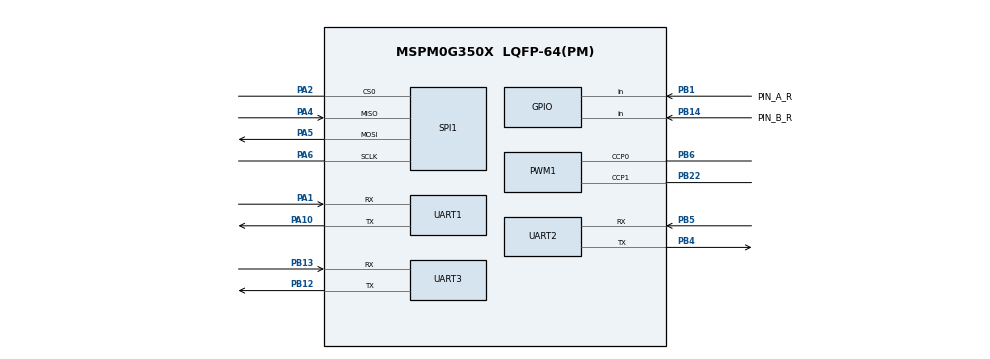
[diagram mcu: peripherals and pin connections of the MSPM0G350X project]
/**
 * @cliArgs --device "MSPM0G350X" --part "Default" --package "LQFP-64(PM)" --product "mspm0_sdk@2.05.01.00"
 * @versions {"tool":"1.24.0+4110"}
 */

/**
 * Import the modules used in this configuration.
 */
const GPIO   = scripting.addModule("/ti/driverlib/GPIO", {}, false);
const GPIO1  = GPIO.addInstance();
const GPIO2  = GPIO.addInstance();
const PWM    = scripting.addModule("/ti/driverlib/PWM", {}, false);
const PWM1   = PWM.addInstance();
const SPI    = scripting.addModule("/ti/driverlib/SPI", {}, false);
const SPI1   = SPI.addInstance();
const SYSCTL = scripting.addModule("/ti/driverlib/SYSCTL");
const TIMER  = scripting.addModule("/ti/driverlib/TIMER", {}, false);
const TIMER1 = TIMER.addInstance();
const UART   = scripting.addModule("/ti/driverlib/UART", {}, false);
const UART1  = UART.addInstance();
const UART2  = UART.addInstance();
const UART3  = UART.addInstance();

/**
 * Write custom configuration values to the imported modules.
 */
const gate7  = system.clockTree["MFCLKGATE"];
gate7.enable = true;

GPIO1.$name                               = "GPIO_ENCODER";
GPIO1.associatedPins.create(4);
GPIO1.associatedPins[0].direction         = "INPUT";
GPIO1.associatedPins[0].interruptEn       = true;
GPIO1.associatedPins[0].polarity          = "RISE";
GPIO1.associatedPins[0].interruptPriority = "0";
GPIO1.associatedPins[0].assignedPort      = "PORTB";
GPIO1.associatedPins[0].$name             = "PIN_A_L";
GPIO1.associatedPins[0].assignedPin       = "23";
GPIO1.associatedPins[1].direction         = "INPUT";
GPIO1.associatedPins[1].assignedPort      = "PORTB";
GPIO1.associatedPins[1].interruptEn       = true;
GPIO1.associatedPins[1].interruptPriority = "0";
GPIO1.associatedPins[1].polarity          = "RISE";
GPIO1.associatedPins[1].$name             = "PIN_B_L";
GPIO1.associatedPins[1].assignedPin       = "27";
GPIO1.associatedPins[2].$name             = "PIN_A_R";
GPIO1.associatedPins[2].direction         = "INPUT";
GPIO1.associatedPins[2].assignedPort      = "PORTB";
GPIO1.associatedPins[2].assignedPin       = "1";
GPIO1.associatedPins[2].interruptEn       = true;
GPIO1.associatedPins[2].polarity          = "RISE";
GPIO1.associatedPins[2].interruptPriority = "0";
GPIO1.associatedPins[2].pin.$assign       = "PB1";
GPIO1.associatedPins[3].$name             = "PIN_B_R";
GPIO1.associatedPins[3].assignedPort      = "PORTB";
GPIO1.associatedPins[3].direction         = "INPUT";
GPIO1.associatedPins[3].assignedPin       = "14";
GPIO1.associatedPins[3].interruptEn       = true;
GPIO1.associatedPins[3].interruptPriority = "0";
GPIO1.associatedPins[3].polarity          = "RISE";
GPIO1.associatedPins[3].pin.$assign       = "PB14";

const Board = scripting.addModule("/ti/driverlib/Board", {}, false);

GPIO2.$name                          = "TB6612";
GPIO2.associatedPins.create(4);
GPIO2.associatedPins[0].$name        = "AIN1";
GPIO2.associatedPins[0].initialValue = "SET";
GPIO2.associatedPins[0].assignedPort = "PORTB";
GPIO2.associatedPins[0].assignedPin  = "8";
GPIO2.associatedPins[1].$name        = "AIN2";
GPIO2.associatedPins[1].initialValue = "SET";
GPIO2.associatedPins[1].assignedPort = "PORTA";
GPIO2.associatedPins[1].assignedPin  = "12";
GPIO2.associatedPins[2].$name        = "BIN1";
GPIO2.associatedPins[2].initialValue = "SET";
GPIO2.associatedPins[2].assignedPort = "PORTA";
GPIO2.associatedPins[2].assignedPin  = "7";
GPIO2.associatedPins[3].$name        = "BIN2";
GPIO2.associatedPins[3].initialValue = "SET";
GPIO2.associatedPins[3].assignedPort = "PORTA";
GPIO2.associatedPins[3].assignedPin  = "18";

PWM1.$name                      = "PWM_0";
PWM1.clockDivider               = 8;
PWM1.timerStartTimer            = true;
PWM1.peripheral.$assign         = "TIMG8";
PWM1.peripheral.ccp0Pin.$assign = "PB6";
PWM1.peripheral.ccp1Pin.$assign = "PB22";
PWM1.PWM_CHANNEL_0.$name        = "ti_driverlib_pwm_PWMTimerCC5";
PWM1.PWM_CHANNEL_0.invert       = true;
PWM1.PWM_CHANNEL_1.$name        = "ti_driverlib_pwm_PWMTimerCC6";
PWM1.PWM_CHANNEL_1.invert       = true;
PWM1.ccp0PinConfig.$name        = "ti_driverlib_gpio_GPIOPinGeneric11";
PWM1.ccp1PinConfig.$name        = "ti_driverlib_gpio_GPIOPinGeneric12";

SPI1.$name                      = "SPI_0";
SPI1.peripheral.$assign         = "SPI0";
SPI1.peripheral.sclkPin.$assign = "PA6";
SPI1.peripheral.mosiPin.$assign = "PA5";
SPI1.peripheral.misoPin.$assign = "PA4";
SPI1.peripheral.cs0Pin.$assign  = "PA2";
SPI1.sclkPinConfig.$name        = "ti_driverlib_gpio_GPIOPinGeneric6";
SPI1.mosiPinConfig.$name        = "ti_driverlib_gpio_GPIOPinGeneric7";
SPI1.misoPinConfig.$name        = "ti_driverlib_gpio_GPIOPinGeneric8";
SPI1.cs0PinConfig.$name         = "ti_driverlib_gpio_GPIOPinGeneric9";

SYSCTL.forceDefaultClkConfig = true;
SYSCTL.clockTreeEn           = true;

TIMER1.$name              = "TIMER_ECO";
TIMER1.timerStartTimer    = true;
TIMER1.timerPeriod        = "20 ms";
TIMER1.timerClkDiv        = 8;
TIMER1.timerMode          = "PERIODIC";
TIMER1.timerClkPrescale   = 100;
TIMER1.interrupts         = ["ZERO"];
TIMER1.peripheral.$assign = "TIMG0";

UART1.$name                    = "UART_0";
UART1.enabledInterrupts        = ["RX"];
UART1.targetBaudRate           = 115200;
UART1.peripheral.$assign       = "UART0";
UART1.peripheral.rxPin.$assign = "PA1";
UART1.peripheral.txPin.$assign = "PA10";
UART1.txPinConfig.$name        = "ti_driverlib_gpio_GPIOPinGeneric4";
UART1.rxPinConfig.$name        = "ti_driverlib_gpio_GPIOPinGeneric5";

UART2.$name                    = "UART_1";
UART2.enabledInterrupts        = ["RX"];
UART2.targetBaudRate           = 115200;
UART2.peripheral.$assign       = "UART1";
UART2.peripheral.rxPin.$assign = "PB5";
UART2.peripheral.txPin.$assign = "PB4";
UART2.txPinConfig.$name        = "ti_driverlib_gpio_GPIOPinGeneric10";
UART2.rxPinConfig.$name        = "ti_driverlib_gpio_GPIOPinGeneric13";

UART3.$name                    = "UART_3";
UART3.enabledInterrupts        = ["RX"];
UART3.targetBaudRate           = 115200;
UART3.peripheral.$assign       = "UART3";
UART3.peripheral.rxPin.$assign = "PB13";
UART3.peripheral.txPin.$assign = "PB12";
UART3.txPinConfig.$name        = "ti_driverlib_gpio_GPIOPinGeneric16";
UART3.rxPinConfig.$name        = "ti_driverlib_gpio_GPIOPinGeneric17";

/**
 * Pinmux solution for unlocked pins/peripherals. This ensures that minor changes to the automatic solver in a future
 * version of the tool will not impact the pinmux you originally saw.  These lines can be completely deleted in order to
 * re-solve from scratch.
 */
GPIO1.associatedPins[0].pin.$suggestSolution = "PB23";
GPIO1.associatedPins[1].pin.$suggestSolution = "PB27";
Board.peripheral.$suggestSolution            = "DEBUGSS";
Board.peripheral.swclkPin.$suggestSolution   = "PA20";
Board.peripheral.swdioPin.$suggestSolution   = "PA19";
GPIO2.associatedPins[0].pin.$suggestSolution = "PB8";
GPIO2.associatedPins[1].pin.$suggestSolution = "PA12";
GPIO2.associatedPins[2].pin.$suggestSolution = "PA7";
GPIO2.associatedPins[3].pin.$suggestSolution = "PA18";
